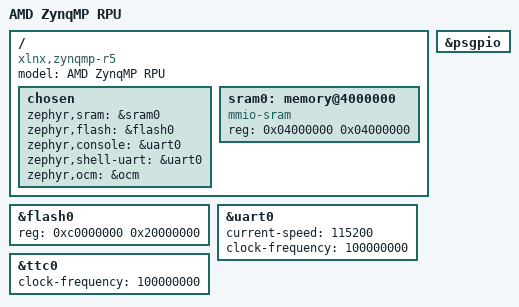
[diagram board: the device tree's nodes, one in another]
/*
 * Copyright (c) 2026 Advanced Micro Devices, Inc.
 *
 * SPDX-License-Identifier: Apache-2.0
 */

/dts-v1/;
#include <arm/xilinx/zynqmp_rpu.dtsi>

/ {
	compatible = "xlnx,zynqmp-r5";
	model = "AMD ZynqMP RPU";

	chosen {
		zephyr,sram = &sram0;
		zephyr,flash = &flash0;
		zephyr,console = &uart0;
		zephyr,shell-uart = &uart0;
		zephyr,ocm = &ocm;
	};

	sram0: memory@4000000 {
		compatible = "mmio-sram";
		reg = <0x04000000 0x04000000>;
	};
};

&flash0 {
	reg = <0xc0000000 0x20000000>;
};

/* UART reference clock (Hz) */
&uart0 {
	current-speed = <115200>;
	clock-frequency = <100000000>;
	status = "okay";
};

&ttc0 {
	clock-frequency = <100000000>;
	status = "okay";
};

&psgpio {
	status = "okay";
};
